# PIC32CM5112SG00048 device description
Architecture: CORTEX-M23; Family: PIC32CM; Series: PIC32CMSG00
Registers are 32-bit, read-write, reset 0x0 unless marked. A register's access mark holds for its fields unless they carry their own. Offsets are from the block's base; [hi:lo] are bit positions; {n}, {i} and the like mark numbered series.

## AT — Anti-Tamper Controller (AT)
Instances: AT 0x4500C000
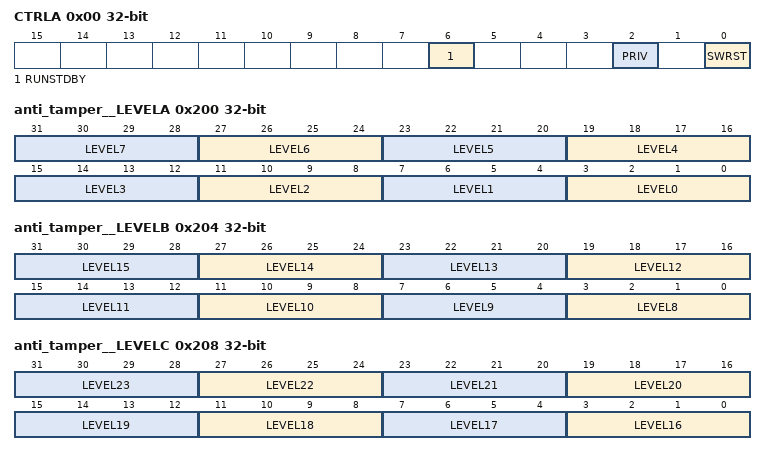
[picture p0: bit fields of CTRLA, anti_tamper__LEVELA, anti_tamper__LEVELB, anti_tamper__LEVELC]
0x00 CTRLA — Control Register A
  [6] RUNSTDBY — RUNSTDBY Enable Bit
  [2] PRIV — Privileged Access Only
    0=AT registers accessible in privileged and unprivileged modes; 1=AT registers only accessible in privileged mode
  [0] SWRST — Software Reset1 = Reset registers , Bus I/F and internal state0 = No effect
{0x100+4i} TAMPER_KEY[{i}] (i=0..15) — Tamper Key n Register
  [31:0] TAMPERKEY — Tamper Key Value
0x200 anti_tamper__LEVELA ro — Tamper levels 0 to 7.
  [4n+3:4n] LEVEL{n} (n=0..7)
0x204 anti_tamper__LEVELB ro — Tamper levels 8 to 15.
  [4n-29:4n-32] LEVEL{n} (n=8..15)
0x208 anti_tamper__LEVELC ro — Tamper levels 16 to 23.
  [4n-61:4n-64] LEVEL{n} (n=16..23)
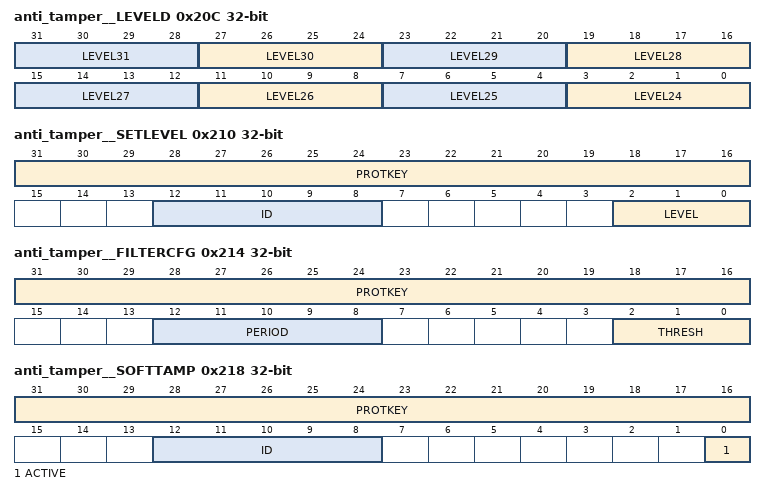
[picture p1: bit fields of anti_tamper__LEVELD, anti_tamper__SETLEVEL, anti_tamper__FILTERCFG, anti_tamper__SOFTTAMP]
0x20C anti_tamper__LEVELD ro — Tamper levels 24 to 31.
  [4n-93:4n-96] LEVEL{n} (n=24..31)
0x210 anti_tamper__SETLEVEL wo — Set tamper level.
  [31:16] PROTKEY — Protection key (0xA84C).
  [12:8] ID — Tamper ID.
  [2:0] LEVEL — Tamper level.
0x214 anti_tamper__FILTERCFG — Filter configuration (threshold, period).
  [31:16] PROTKEY — Protection key (0x92F5).
  [12:8] PERIOD
  [2:0] THRESH — Threshold.
0x218 anti_tamper__SOFTTAMP — Software triggered tamper.
  [31:16] PROTKEY — Protection key (0x4BEE).
  [12:8] ID — Tamper ID.
  [0] ACTIVE — Tamper active.
0x21C anti_tamper__RAWSTAT ro — Raw status.
0x220 anti_tamper__STAT reset 0x1 — Status (write to clear).
0x224 anti_tamper__TIMESTAMP ro — Timestamp for the last tamper.
0x228 anti_tamper__FILTERCNT ro — Current value of filter counter.
0x22C anti_tamper__SOFTINFO — Register for software purpose only.
0x230 anti_tamper__TAMPERFLAG — The 1-bit TAMPERFLAG register directly controls the TAMPER_FLAG output.
  [0] TAMPERFLAG
0x234 anti_tamper__SOFTRESET ro (atomic set) — Reading the SOFTLVL4 register returns 1 if any active soft tamper has a level of 4 or above.
  [0] SOFTRESET

## BROMC — ARM GF55LPx Boot ROM Controller Macro
Instances: BROMC 0x44804000
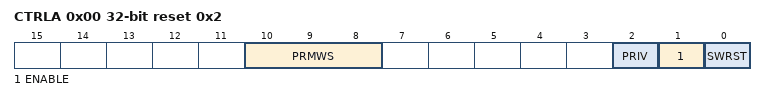
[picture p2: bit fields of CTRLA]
0x00 CTRLA reset 0x2 — Control A REGISTER
  [10:8] PRMWS — ROM Access Time Wait State
    0=No wait states, single cycle access; 1=Access time extended 2 clock cycles; 2=Access time extended to 3 clock cycles; 7=Access time extended to 8 clock cycles
  [2] PRIV — Privileged Access Only
    0=Macro register accessible in privileged and unprivileged modes; 1=Macro registers only accessible in privileged mode
  [1] ENABLE — Enable bit
    0=Disable ROM read access and power down the ROM. The ROM PGEN input is driven high. The ROM will clamp outputs to 1 and disable all internal current sinks. Refer to the ROM compiler specification for details on powering down the ROM.; 1=Enable ROM read access, power up the ROM. The ROM PGEN input is driven low.
  [0] SWRST — Software Reset bit
0x04 UCFG ro reset 0x1 — User Configuration REGISTER
  [0] BCRCDIS — Boot CRC Disable
    0=Boot ROM content is CRC verified by the ROM controller, status is reported to the DSU. On CRC failure, the controller blocks access to the ROM controller.; 1=No CRC verification at Boot

## CAN_MRAM_RXBE — Control Area Network
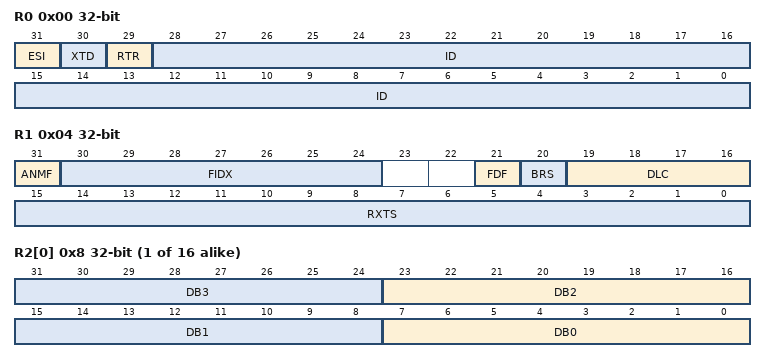
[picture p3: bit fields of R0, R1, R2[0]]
0x00 R0 — Rx Buffer and FIFO Element 0
  [31] ESI — Error State Indicator
  [30] XTD — Extended Identifier
  [29] RTR — Remote Transmission Request
  [28:0] ID — Identifier
0x04 R1 — Rx Buffer and FIFO Element 1
  [31] ANMF — Accepted Non-matching Frame
  [30:24] FIDX — Filter Index
  [21] FDF — FD Format
  [20] BRS — Bit Rate Search
  [19:16] DLC — Data Length Code
  [15:0] RXTS — Rx Timestamp
{0x8+4i} R2[{i}] (i=0..15) — Rx Buffer and FIFO Element Data
  [8n+7:8n] DB{n} (n=0..3) — Data Byte {n}

## CAN_MRAM_SIDFE — Control Area Network
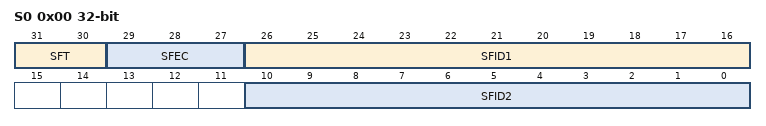
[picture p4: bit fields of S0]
0x00 S0 — Standard Message ID Filter Element
  [31:30] SFT — Standard Filter Type
    0=RANGE (Range filter from SFID1 to SFID2); 1=DUAL (Dual ID filter for SFID1 or SFID2); 2=CLASSIC (Classic filter)
  [29:27] SFEC — Standard Filter Element Configuration
    0=DISABLE (Disable filter element); 1=STF0M (Store in Rx FIFO 0 if filter match); 2=STF1M (Store in Rx FIFO 1 if filter match); 3=REJECT (Reject ID if filter match); 4=PRIORITY (Set priority if filter match); 5=PRIF0M (Set priority and store in FIFO 0 if filter match); 6=PRIF1M (Set priority and store in FIFO 1 if filter match); 7=STRXBUF (Store into Rx Buffer)
  [26:16] SFID1 — Standard Filter ID 1
  [10:0] SFID2 — Standard Filter ID 2
